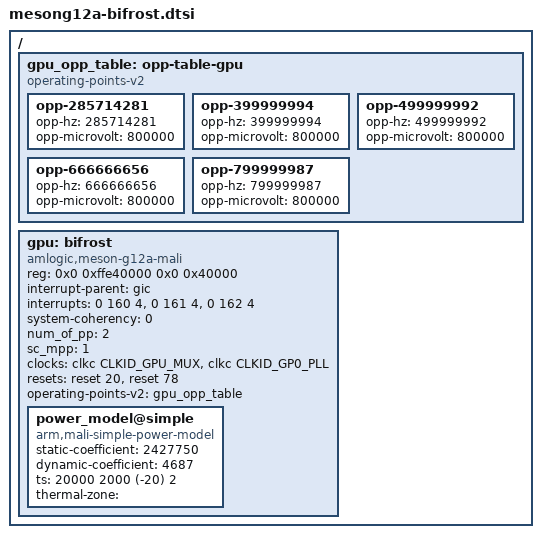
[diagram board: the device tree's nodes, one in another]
/*
 * arch/arm64/boot/dts/amlogic/mesong12a-bifrost.dtsi
 *
 * Copyright (C) 2017 Amlogic, Inc. All rights reserved.
 *
 * This program is free software; you can redistribute it and/or modify
 * it under the terms of the GNU General Public License as published by
 * the Free Software Foundation; either version 2 of the License, or
 * (at your option) any later version.
 *
 * This program is distributed in the hope that it will be useful, but WITHOUT
 * ANY WARRANTY; without even the implied warranty of MERCHANTABILITY or
 * FITNESS FOR A PARTICULAR PURPOSE.  See the GNU General Public License for
 * more details.
 *
 */

/ {

	gpu_opp_table: opp-table-gpu {
		compatible = "operating-points-v2";

		opp-285714281 {
			opp-hz = /bits/ 64 <285714281>;
			opp-microvolt = <800000>;
		};
		opp-399999994 {
			opp-hz = /bits/ 64 <399999994>;
			opp-microvolt = <800000>;
		};
		opp-499999992 {
			opp-hz = /bits/ 64 <499999992>;
			opp-microvolt = <800000>;
		};
		opp-666666656 {
			opp-hz = /bits/ 64 <666666656>;
			opp-microvolt = <800000>;
		};
		opp-799999987 {
			opp-hz = /bits/ 64 <799999987>;
			opp-microvolt = <800000>;
		};
	};

	gpu:bifrost {
		compatible = "amlogic,meson-g12a-mali", "arm,mali-bifrost";
		reg = <0x0 0xffe40000 0x0 0x40000>;
		interrupt-parent = <&gic>;
		interrupts = <0 160 4>, <0 161 4>, <0 162 4>;
		interrupt-names = "GPU", "MMU", "JOB";
		/* ACE-Lite = 0; ACE = 1; No-coherency = 31; */
		system-coherency = <0>;

		num_of_pp = <2>;
		sc_mpp = <1>; /* number of shader cores used most of time. */
		clocks = <&clkc CLKID_GPU_MUX &clkc CLKID_GP0_PLL>;
		clock-names = "gpu_mux","gp0_pll";
		resets = <&reset 20>, <&reset 78>;
		operating-points-v2 = <&gpu_opp_table>;
		#cooling-cells = <2>;

		power_model@simple {
			compatible = "arm,mali-simple-power-model";
			static-coefficient = <2427750>;
			dynamic-coefficient = <4687>;
			ts = <20000 2000 (-20) 2>;
			thermal-zone = "";
		};

	};

};/* end of / */
